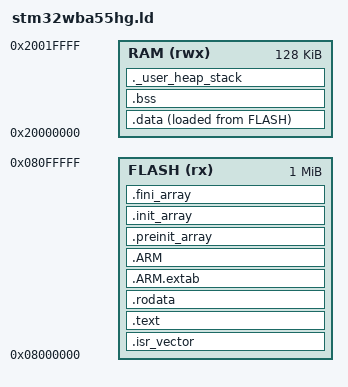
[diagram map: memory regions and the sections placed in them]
/* Linker script for STM32WBA55HG */
/* 1MB Flash, 128KB SRAM (single region, matching working project) */

MEMORY
{
    FLASH (rx)   : ORIGIN = 0x08000000, LENGTH = 1024K
    RAM   (rwx)  : ORIGIN = 0x20000000, LENGTH = 128K
}

/* Entry point */
ENTRY(Reset_Handler)

/* Highest address of the stack — top of RAM */
_estack = ORIGIN(RAM) + LENGTH(RAM);

/* Minimum heap and stack sizes */
_Min_Heap_Size  = 0x400;
_Min_Stack_Size = 0x3000;  /* 12KB — BLE stack needs significant depth */

SECTIONS
{
    /* Vector table and code go into FLASH */
    .isr_vector :
    {
        . = ALIGN(4);
        KEEP(*(.isr_vector))
        . = ALIGN(4);
    } >FLASH

    .text :
    {
        . = ALIGN(4);
        *(.text)
        *(.text*)
        *(.glue_7)
        *(.glue_7t)

        KEEP(*(.init))
        KEEP(*(.fini))

        . = ALIGN(4);
        _etext = .;
    } >FLASH

    .rodata :
    {
        . = ALIGN(4);
        *(.rodata)
        *(.rodata*)
        . = ALIGN(4);
    } >FLASH

    /* ARM exception handling — needed by some C library functions */
    .ARM.extab :
    {
        *(.ARM.extab* .gnu.linkonce.armextab.*)
    } >FLASH

    .ARM :
    {
        __exidx_start = .;
        *(.ARM.exidx*)
        __exidx_end = .;
    } >FLASH

    /* C constructors/destructors — MUST be in FLASH */
    .preinit_array :
    {
        PROVIDE_HIDDEN(__preinit_array_start = .);
        KEEP(*(.preinit_array*))
        PROVIDE_HIDDEN(__preinit_array_end = .);
    } >FLASH

    .init_array :
    {
        PROVIDE_HIDDEN(__init_array_start = .);
        KEEP(*(SORT(.init_array.*)))
        KEEP(*(.init_array*))
        PROVIDE_HIDDEN(__init_array_end = .);
    } >FLASH

    .fini_array :
    {
        PROVIDE_HIDDEN(__fini_array_start = .);
        KEEP(*(SORT(.fini_array.*)))
        KEEP(*(.fini_array*))
        PROVIDE_HIDDEN(__fini_array_end = .);
    } >FLASH

    /* Used by startup to initialize .data */
    _sidata = LOADADDR(.data);

    /* Initialized data — loaded from FLASH, lives in RAM */
    .data :
    {
        . = ALIGN(4);
        _sdata = .;
        *(.data)
        *(.data*)
        . = ALIGN(4);
        _edata = .;
    } >RAM AT> FLASH

    /* Uninitialized data — zero-filled in RAM */
    .bss :
    {
        . = ALIGN(4);
        _sbss = .;
        __bss_start__ = _sbss;
        *(.bss)
        *(.bss*)
        *(.bss_ble)
        *(.bss_ble*)
        *(COMMON)
        . = ALIGN(4);
        _ebss = .;
        __bss_end__ = _ebss;
    } >RAM

    /* Heap grows up, stack grows down — check they don't collide */
    ._user_heap_stack :
    {
        . = ALIGN(8);
        PROVIDE(end = .);
        PROVIDE(_end = .);
        . = . + _Min_Heap_Size;
        . = . + _Min_Stack_Size;
        . = ALIGN(8);
    } >RAM

    /* Provide dummy symbols for SRAM2 BSS zeroing (now in main BSS) */
    _sbss_ble = _sbss;
    _ebss_ble = _sbss;  /* Empty — BLE buffers are in regular BSS now */

    /* Discard debug sections from standard libraries */
    /DISCARD/ :
    {
        libc.a(*)
        libm.a(*)
        libgcc.a(*)
    }

    .ARM.attributes 0 : { *(.ARM.attributes) }
}
